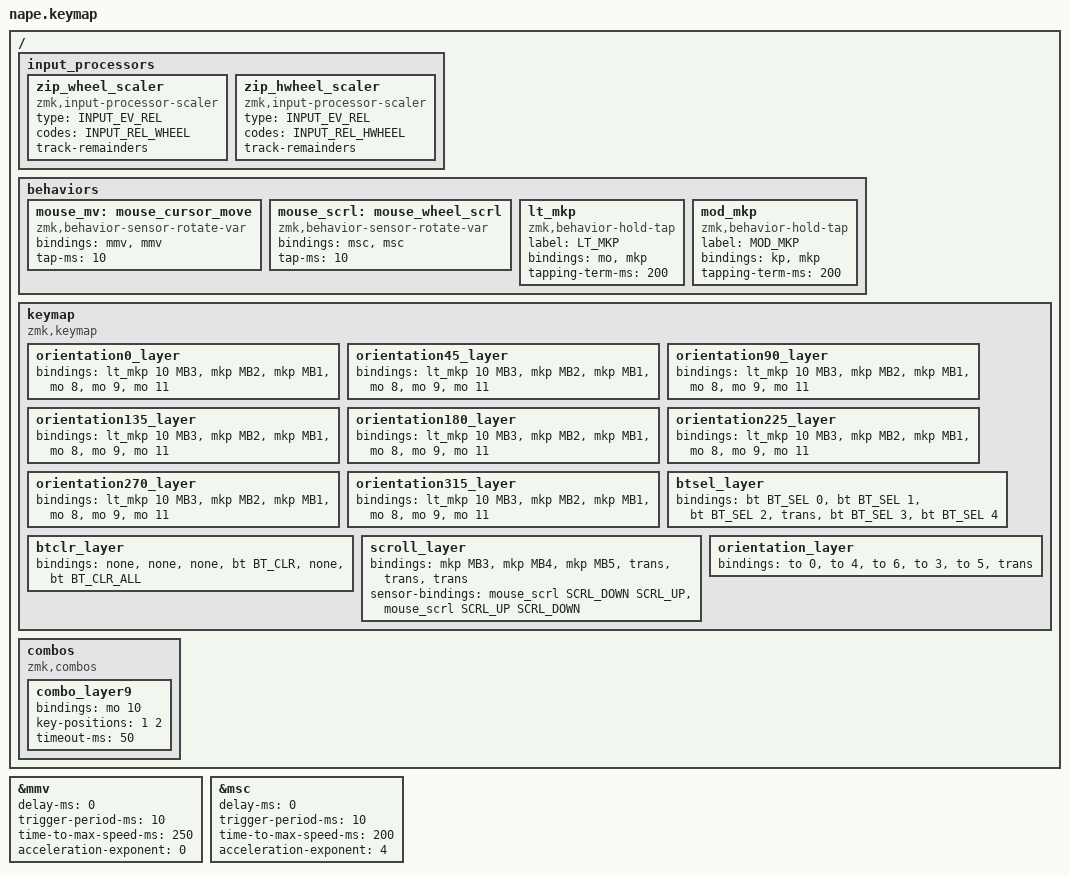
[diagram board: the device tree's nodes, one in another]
#include <dt-bindings/zmk/mouse.h>

// マウス移動とスクロールのデフォルト値を設定

#define ZMK_POINTING_DEFAULT_MOVE_VAL 100 //デフォルト800
#define ZMK_POINTING_DEFAULT_SCRL_VAL 50

#include <input/processors.dtsi>
#include <zephyr/dt-bindings/input/input-event-codes.h>
#include <behaviors.dtsi>
#include <dt-bindings/zmk/bt.h>
#include <dt-bindings/zmk/keys.h>
#include <dt-bindings/zmk/pointing.h>

// マウス移動の設定

&mmv {

    delay-ms = <0>;              // 遅延なし
    trigger-period-ms = <10>;    // 10ミリ秒ごとにトリガー
    // ボールを動かし始めてから最大速度に達するまでの時間を設定（例: 400ミリ秒）
    // この値が大きいほど、加速が緩やかになります。

    time-to-max-speed-ms = <250>;  // デフォルト0 即座に最大速度に
    // 加速カーブの指数。1より大きいと、後からグッと伸びるようになります。
    // まずは1（線形）か2（緩やかな指数）から試すのがおすすめです。

    acceleration-exponent = <0>;  // デフォルト0 線形加速
};

// マウススクロールの設定

&msc {
    delay-ms = <0>;              // 遅延なし
    trigger-period-ms = <10>;    // 10ミリ秒ごとにトリガー
    time-to-max-speed-ms = <200>;  // 即座に最大速度に
    acceleration-exponent = <4>;  // 加速なし
};

// 入力プロセッサーの設定

/ {
    input_processors {

        // 垂直スクロールのスケーラー

        zip_wheel_scaler: zip_wheel_scaler {
            compatible = "zmk,input-processor-scaler";
            #input-processor-cells = <2>;
            type = <INPUT_EV_REL>;
            codes = <INPUT_REL_WHEEL>;
            track-remainders;
        };

        // 水平スクロールのスケーラー

        zip_hwheel_scaler: zip_hwheel_scaler {
            compatible = "zmk,input-processor-scaler";
            #input-processor-cells = <2>;
            type = <INPUT_EV_REL>;
            codes = <INPUT_REL_HWHEEL>;
            track-remainders;
        };
    };
};

// カスタムビヘイビアの定義

/ {
    behaviors {
        // マウスカーソル移動の回転検出

        mouse_mv: mouse_cursor_move {
            compatible = "zmk,behavior-sensor-rotate-var";
            #sensor-binding-cells = <2>;
            bindings = <&mmv>, <&mmv>;

            tap-ms = <10>;
        };

        // マウスホイールスクロールの回転検出

        mouse_scrl: mouse_wheel_scrl {
            compatible = "zmk,behavior-sensor-rotate-var";
            #sensor-binding-cells = <2>;
            bindings = <&msc>, <&msc>;

            tap-ms = <10>;
        };

        lt_mkp: lt_mkp {
            compatible = "zmk,behavior-hold-tap";
            label = "LT_MKP";
            bindings = <&mo>, <&mkp>;

            #binding-cells = <2>;
            tapping-term-ms = <200>;
        };

        mod_mkp: mod_mkp {
            compatible = "zmk,behavior-hold-tap";
            label = "MOD_MKP";
            bindings = <&kp>, <&mkp>;

            #binding-cells = <2>;
            tapping-term-ms = <200>;
        };
    };

    // キーマップの定義

    keymap {
        compatible = "zmk,keymap";

        // レイヤー0（時計回り90°）

        orientation0_layer {
            bindings = <
&lt_mkp 10 MB3  &mkp MB2  &mkp MB1  &mo 8  &mo 9  &mo 11
            >;
        };

        orientation45_layer {
            bindings = <
&lt_mkp 10 MB3  &mkp MB2  &mkp MB1  &mo 8  &mo 9  &mo 11
            >;
        };

        orientation90_layer {
            bindings = <
&lt_mkp 10 MB3  &mkp MB2  &mkp MB1  &mo 8  &mo 9  &mo 11
            >;
        };

        orientation135_layer {
            bindings = <
&lt_mkp 10 MB3  &mkp MB2  &mkp MB1  &mo 8  &mo 9  &mo 11
            >;
        };

        orientation180_layer {
            bindings = <
&lt_mkp 10 MB3  &mkp MB2  &mkp MB1  &mo 8  &mo 9  &mo 11
            >;
        };

        orientation225_layer {
            bindings = <
&lt_mkp 10 MB3  &mkp MB2  &mkp MB1  &mo 8  &mo 9  &mo 11
            >;
        };

        orientation270_layer {
            bindings = <
&lt_mkp 10 MB3  &mkp MB2  &mkp MB1  &mo 8  &mo 9  &mo 11
            >;
        };

        orientation315_layer {
            bindings = <
&lt_mkp 10 MB3  &mkp MB2  &mkp MB1  &mo 8  &mo 9  &mo 11
            >;
        };

        btsel_layer {
            bindings = <
&bt BT_SEL 0  &bt BT_SEL 1  &bt BT_SEL 2  &trans  &bt BT_SEL 3  &bt BT_SEL 4
            >;
        };

        btclr_layer {
            bindings = <
&none  &none  &none  &bt BT_CLR  &none  &bt BT_CLR_ALL
            >;
        };

        scroll_layer {
            bindings = <
&mkp MB3  &mkp MB4  &mkp MB5  &trans  &trans  &trans
            >;

            // トラックボールの動きをスクロールに変換

            sensor-bindings =
                <&mouse_scrl SCRL_DOWN SCRL_UP>,
                <&mouse_scrl SCRL_UP SCRL_DOWN>;
        };

        orientation_layer {
            bindings = <
&to 0  &to 4  &to 6  &to 3  &to 5  &trans
            >;
        };
    };
};

/ {
    combos {
        compatible = "zmk,combos";

        // Key1、2同時押しでスクロールレイヤーへ

        combo_layer9 {
            bindings = <&mo 10>;
            key-positions = <1 2>;
            timeout-ms = <50>;
        };
    };
};
